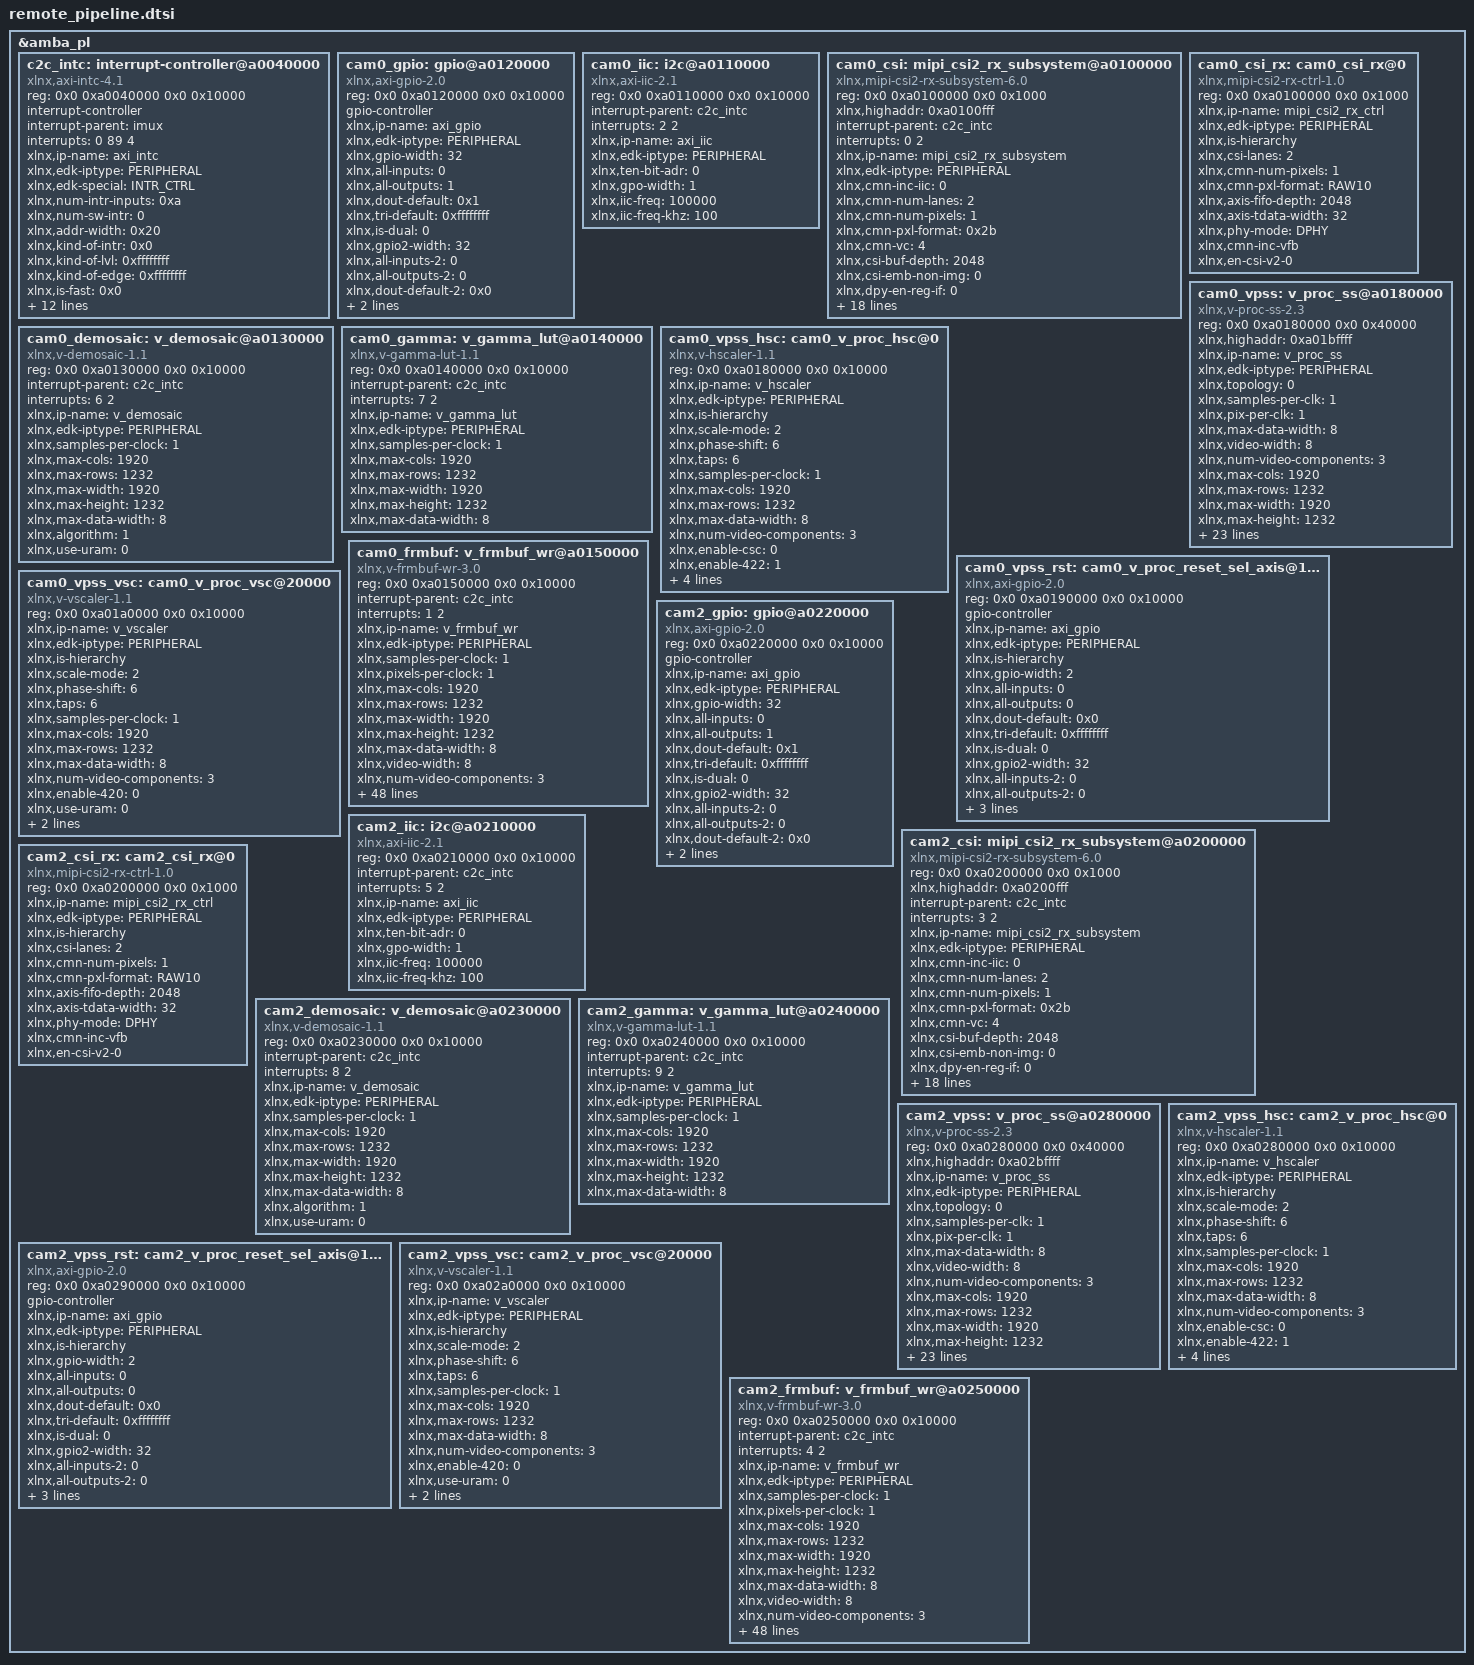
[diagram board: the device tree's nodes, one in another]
/*
 * SPDX-License-Identifier: MIT
 * Copyright (C) 2025-2026, Opsero Electronic Design Inc.  All rights reserved.
 *
 * remote_pipeline.dtsi - the "User DTS" of the Vitis System Device Tree (SDT) flow:
 * the two MIPI camera pipelines that live in the FPGA of the AUBoard 15P, described
 * for the STANDALONE (bare-metal) domain of the ZCU106.
 *
 * WHY THIS FILE EXISTS
 * --------------------
 * The ZCU106 XSA (Vivado/zcu106/c2c_wrapper.xsa) knows about the PS, the AXI
 * Chip2Chip core and one GPIO - and nothing else.  Every video IP of this design
 * sits in the OTHER FPGA and is reached through the Chip2Chip AXI4-Lite window at
 * 0xA000_0000.  Vitis cannot learn about those IP from the XSA, so we hand it this
 * device tree source: Vitis passes it to sdtgen as the "User DTS" (Create Platform
 * Component -> Advanced Options -> User DTS; on the command line the sdtgen hook
 * VITIS_SDT_INCLUDE_DTS, see Vitis/py/build-vitis.py).  Lopper then matches the
 * compatible strings to the driver YAML files of embeddedsw, pulls the drivers into
 * the BSP and generates their config tables (xv_frmbufwr_g.c, xiic_g.c, ...) with
 * the addresses below - exactly as if the IP were in the ZCU106.
 *
 * WHERE THE VALUES COME FROM
 * --------------------------
 * Every address, parameter and interrupt number below is the value the AUBoard block
 * design was built with.  Authoritative source: docs/link_contract_deviations.md
 * ("Phase 2") and Vivado/src/bd/bd_fpga.tcl, which prints them at build time on the
 * lines that start with "INFO: [cam]" and "INFO: [map]".  The Linux description of
 * the same hardware is Yocto/overlays/c2c-cams.dtso - same addresses, same interrupt
 * numbers, different (Linux) property sets.
 *
 * The property NAMES and the node shapes are the ones the AMD tools themselves
 * produce: they were harvested from an SDT generated with sdtgen from an XSA of the
 * rpi-camera-fmc reference design, which has the same IP instantiated locally, and
 * cross-checked against the "required:" list of each driver's YAML binding under
 * <Vitis>/data/embeddedsw/XilinxProcessorIPLib/drivers/ (data/<driver>.yaml).
 *
 * WHAT IS *NOT* HERE
 * ------------------
 * - clocks / clock-names: the standalone config structs do not carry a clock, and
 *   the clocks of these IP are generated on the AUBoard, where the ZCU106 tree has
 *   no phandle for them.  (The Linux overlay does need them, and invents fixed
 *   clocks for exactly that reason.)
 * - reset-gpios: a Linux-only binding.  Bare metal releases the resets by hand,
 *   through the per-pipeline axi_gpio - see Vitis/common/src/pipe.c.
 * - the axis_subset_converter (RAW10 -> 8 bit) has no register interface and no node.
 *
 * READ THIS BEFORE TOUCHING THE HARDWARE
 * --------------------------------------
 * A video IP whose reset bit in the GPIO of its pipeline is 0 does NOT answer on
 * AXI4-Lite, and neither does anything behind a link that is down.  Such an access
 * never completes and hangs the A53.  The application therefore checks the link
 * status register (0xA100_0000, in the ZCU106 XSA) first and releases every reset
 * before it touches an IP.  Nothing in this file causes an access by itself - the
 * standalone BSP only generates data structures.
 *
 * MEMORY MAP (repeated here so the file stands on its own)
 *
 *   0xA004_0000  64K   axi_intc (10 inputs, all level) -> pl_ps_irq0[0] = GIC SPI 89
 *   CAM0 0xA010_0000 / CAM2 0xA020_0000, offsets inside a pipeline:
 *     +0x0_0000  64K   mipi_csi2_rx_subsystem (decodes 4K)
 *     +0x1_0000  64K   axi_iic        (sensor bus, IMX219 at 0x10)
 *     +0x2_0000  64K   axi_gpio       (camera enable + the resets of the video IP)
 *     +0x3_0000  64K   v_demosaic
 *     +0x4_0000  64K   v_gamma_lut
 *     +0x5_0000  64K   v_frmbuf_wr
 *     +0x8_0000 256K   v_proc_ss      (+0x0_0000 h scaler, +0x1_0000 reset GPIO,
 *                                      +0x2_0000 v scaler)
 *
 *   axi_intc inputs:  0 CAM0 csi   1 CAM0 frmbuf_wr   2 CAM0 iic
 *                     3 CAM2 csi   4 CAM2 frmbuf_wr   5 CAM2 iic
 *                     6 CAM0 demosaic   7 CAM0 gamma
 *                     8 CAM2 demosaic   9 CAM2 gamma
 */

/ {
};

&amba_pl {

	/* =====================================================================
	 * The interrupt controller of the remote design.
	 *
	 * Its "irq" output crosses the link on axi_c2c_m2s_intr_in[0] and lands
	 * on the ZCU106 as pl_ps_irq0[0] = GIC SPI 89, level, active high.  The
	 * parent is &imux, the interrupt multiplexer node of zynqmp.dtsi - the
	 * same parent the AMD tools give a PL interrupt controller in a
	 * single-FPGA design (three cells: 0 = SPI, 89, 4 = level high).
	 *
	 * Consumers below use two cells, <input, sense>, sense 2 = level high.
	 *
	 * What this buys the BSP: every remote IP gets IntrId and IntrParent in
	 * its generated config struct, with IntrParent = this base address with
	 * bit 0 set (lopper's "parent is an AXI INTC, not the GIC" marker), i.e.
	 * 0xa0040001.  See docs/source/baremetal.md for why the demo application
	 * nevertheless POLLS: XSetupInterruptSystem() cannot wire an AXI INTC
	 * that hangs below the GIC on a Cortex-A53.
	 * ===================================================================== */
	c2c_intc: interrupt-controller@a0040000 {
		compatible = "xlnx,axi-intc-4.1", "xlnx,xps-intc-1.00.a";
		reg = <0x0 0xa0040000 0x0 0x10000>;
		status = "okay";
		interrupt-controller;
		#interrupt-cells = <2>;
		interrupt-parent = <&imux>;
		interrupts = <0 89 4>;
		interrupt-names = "irq";
		xlnx,ip-name = "axi_intc";
		xlnx,edk-iptype = "PERIPHERAL";
		xlnx,edk-special = "INTR_CTRL";
		xlnx,num-intr-inputs = <0xa>;
		xlnx,num-sw-intr = <0>;
		xlnx,addr-width = <0x20>;
		/* C_KIND_OF_INTR of the IP is 0xFFFFFC00; masked to the 10 inputs
		 * that exist this is 0: every input is LEVEL sensitive. */
		xlnx,kind-of-intr = <0x0>;
		xlnx,kind-of-lvl = <0xffffffff>;
		xlnx,kind-of-edge = <0xffffffff>;
		xlnx,is-fast = <0x0>;
		xlnx,has-fast = <0>;
		xlnx,ivar-rst-val = <0x10>;
		xlnx,ivar-reset-value = <0x10>;
		xlnx,has-ivr = <1>;
		xlnx,has-sie = <1>;
		xlnx,has-cie = <1>;
		xlnx,has-ipr = <1>;
		xlnx,has-ilr = <0>;
		xlnx,irq-is-level = <1>;
		xlnx,irq-active = <0x1>;
		xlnx,en-cascade-mode = <0>;
		xlnx,cascade-master = <0>;
	};

	/* =====================================================================
	 * CAM0 - 0xA010_0000
	 * ===================================================================== */

	/* Camera enable and the resets of the video IP.  32 bits, all outputs,
	 * reset value 0x1 (camera on, every video IP held in reset).
	 *   bit 0 camera enable (active high)   bit 3 v_proc_ss reset (low)
	 *   bit 2 v_demosaic reset (active low) bit 4 v_gamma_lut reset (low)
	 *   bit 6 v_frmbuf_wr reset (active low)
	 * No interrupt: C_INTERRUPT_PRESENT is 0. */
	cam0_gpio: gpio@a0120000 {
		compatible = "xlnx,axi-gpio-2.0", "xlnx,xps-gpio-1.00.a";
		reg = <0x0 0xa0120000 0x0 0x10000>;
		status = "okay";
		gpio-controller;
		#gpio-cells = <2>;
		xlnx,ip-name = "axi_gpio";
		xlnx,edk-iptype = "PERIPHERAL";
		xlnx,gpio-width = <32>;
		xlnx,all-inputs = <0>;
		xlnx,all-outputs = <1>;
		xlnx,dout-default = <0x1>;
		xlnx,tri-default = <0xffffffff>;
		xlnx,is-dual = <0>;
		xlnx,gpio2-width = <32>;
		xlnx,all-inputs-2 = <0>;
		xlnx,all-outputs-2 = <0>;
		xlnx,dout-default-2 = <0x0>;
		xlnx,tri-default-2 = <0xffffffff>;
		xlnx,interrupt-present = <0>;
	};

	/* Sensor bus: 100 kHz, 7 bit addressing, one AXI IIC per camera. */
	cam0_iic: i2c@a0110000 {
		compatible = "xlnx,axi-iic-2.1", "xlnx,xps-iic-2.00.a";
		reg = <0x0 0xa0110000 0x0 0x10000>;
		status = "okay";
		interrupt-parent = <&c2c_intc>;
		interrupts = <2 2>;
		interrupt-names = "iic2intc_irpt";
		#address-cells = <1>;
		#size-cells = <0>;
		xlnx,ip-name = "axi_iic";
		xlnx,edk-iptype = "PERIPHERAL";
		xlnx,ten-bit-adr = <0>;
		xlnx,gpo-width = <1>;
		xlnx,iic-freq = <100000>;
		xlnx,iic-freq-khz = <100>;
	};

	/* MIPI CSI-2 RX subsystem: 2 lanes, RAW10 (data type 0x2B), 1 pixel per
	 * clock, video format bridge in, all virtual channels, CSI-2 v2.0, line
	 * buffer 2048, D-PHY 420 Mb/s, no D-PHY register interface.  The IP
	 * decodes 4K of its 64K slot (the CSI-2 RX controller), hence the reg
	 * size and highaddr below.
	 *
	 * KNOWN TOOL ISSUE (Vitis 2025.2, NOT caused by this file): the driver's
	 * binding (mipicsiss_v1_14/data/mipicsiss.yaml) has 26 entries in its
	 * "required:" list, but XCsiSs_Config only has 24 slots in a design with
	 * no separate MIPI RX PHY IP - the last three fields of the struct are
	 * behind "#if (XPAR_XMIPI_RX_PHY_NUM_INSTANCES > 0)".  The generated
	 * xcsiss_g.c therefore overflows the struct ("excess elements in struct
	 * initializer" at build time) and EnableVCx / IntrId / IntrParent of
	 * XCsiSs_Config come out wrong.  Any design with a local
	 * mipi_csi2_rx_subsystem 6.0 hits this.  It does not matter here: the
	 * subsystem needs no register write to receive and the application never
	 * uses the XCsiSs driver (as in the rpi-camera-fmc reference design).
	 * Do not trust XCsiSs_Config until AMD fixes the binding. */
	cam0_csi: mipi_csi2_rx_subsystem@a0100000 {
		compatible = "xlnx,mipi-csi2-rx-subsystem-6.0",
			     "xlnx,mipi-csi2-rx-subsystem-5.0";
		reg = <0x0 0xa0100000 0x0 0x1000>;
		xlnx,highaddr = <0xa0100fff>;
		status = "okay";
		interrupt-parent = <&c2c_intc>;
		interrupts = <0 2>;
		interrupt-names = "csirxss_csi_irq";
		xlnx,ip-name = "mipi_csi2_rx_subsystem";
		xlnx,edk-iptype = "PERIPHERAL";
		xlnx,cmn-inc-iic = <0>;
		xlnx,cmn-num-lanes = <2>;
		xlnx,cmn-num-pixels = <1>;
		xlnx,cmn-pxl-format = <0x2b>;
		xlnx,cmn-vc = <4>;
		xlnx,csi-buf-depth = <2048>;
		xlnx,csi-emb-non-img = <0>;
		xlnx,dpy-en-reg-if = <0>;
		xlnx,dpy-line-rate = <420>;
		xlnx,hs-line-rate = <420>;
		xlnx,hs-settle-ns = <158>;
		xlnx,csi-en-crc = <1>;
		xlnx,csi-en-activelanes = <0>;
		xlnx,en-csi-v2 = <1>;
		xlnx,dphy-lanes = <2>;
		xlnx,max-lanes = <2>;
		xlnx,ppc = <1>;
		xlnx,vc = <4>;
		xlnx,en-vcx = <0>;
		xlnx,csi-pxl-format = <0x2b>;
		xlnx,axis-tdata-width = <32>;
		xlnx,cmn-inc-vfb;
		xlnx,vfb;
		xlnx,en-csi-v2-0;
		csirx-present = <1>;
		csirx-connected = <&cam0_csi_rx>;
	};

	/* The CSI-2 RX controller sub-core of the subsystem above.  It has no
	 * driver of its own; the subsystem driver reaches it through
	 * csirx-connected, and lopper needs the node to resolve that phandle. */
	cam0_csi_rx: cam0_csi_rx@0 {
		compatible = "xlnx,mipi-csi2-rx-ctrl-1.0";
		reg = <0x0 0xa0100000 0x0 0x1000>;
		status = "okay";
		xlnx,ip-name = "mipi_csi2_rx_ctrl";
		xlnx,edk-iptype = "PERIPHERAL";
		xlnx,is-hierarchy;
		xlnx,csi-lanes = <2>;
		xlnx,cmn-num-pixels = <1>;
		xlnx,cmn-pxl-format = "RAW10";
		xlnx,axis-fifo-depth = <2048>;
		xlnx,axis-tdata-width = <32>;
		xlnx,phy-mode = "DPHY";
		xlnx,cmn-inc-vfb;
		xlnx,en-csi-v2-0;
	};

	/* Bayer -> RGB.  8 bit, 1 sample per clock, max 1920 x 1232,
	 * ALGORITHM 1, zipper removal on.  Bayer phase is a run-time register
	 * (RGGB = 0 for the IMX219). */
	cam0_demosaic: v_demosaic@a0130000 {
		compatible = "xlnx,v-demosaic-1.1", "xlnx,v-demosaic";
		reg = <0x0 0xa0130000 0x0 0x10000>;
		status = "okay";
		interrupt-parent = <&c2c_intc>;
		interrupts = <6 2>;
		interrupt-names = "interrupt";
		xlnx,ip-name = "v_demosaic";
		xlnx,edk-iptype = "PERIPHERAL";
		xlnx,samples-per-clock = <1>;
		xlnx,max-cols = <1920>;
		xlnx,max-rows = <1232>;
		xlnx,max-width = <1920>;
		xlnx,max-height = <1232>;
		xlnx,max-data-width = <8>;
		xlnx,algorithm = <1>;
		xlnx,use-uram = <0>;
	};

	/* Gamma LUT.  8 bit, 1 sample per clock, max 1920 x 1232.  The three
	 * 256-entry tables live at +0x800 / +0x1000 / +0x1800 and power up
	 * LINEAR - the application loads a real curve. */
	cam0_gamma: v_gamma_lut@a0140000 {
		compatible = "xlnx,v-gamma-lut-1.1", "xlnx,v-gamma-lut";
		reg = <0x0 0xa0140000 0x0 0x10000>;
		status = "okay";
		interrupt-parent = <&c2c_intc>;
		interrupts = <7 2>;
		interrupt-names = "interrupt";
		xlnx,ip-name = "v_gamma_lut";
		xlnx,edk-iptype = "PERIPHERAL";
		xlnx,samples-per-clock = <1>;
		xlnx,max-cols = <1920>;
		xlnx,max-rows = <1232>;
		xlnx,max-width = <1920>;
		xlnx,max-height = <1232>;
		xlnx,max-data-width = <8>;
	};

	/* Video Processing Subsystem, scaler only (C_TOPOLOGY 0), polyphase,
	 * 6 taps / 64 phases horizontal and vertical, 8 bit, 1 sample per clock,
	 * max 1920 x 1232, no colour space conversion, RGB / YUV 4:4:4 only,
	 * no DMA.  The 256K window holds the three sub-cores below. */
	cam0_vpss: v_proc_ss@a0180000 {
		compatible = "xlnx,v-proc-ss-2.3", "xlnx,v-vpss-scaler-2.2";
		reg = <0x0 0xa0180000 0x0 0x40000>;
		xlnx,highaddr = <0xa01bffff>;
		status = "okay";
		xlnx,ip-name = "v_proc_ss";
		xlnx,edk-iptype = "PERIPHERAL";
		xlnx,topology = <0>;
		xlnx,samples-per-clk = <1>;
		xlnx,pix-per-clk = <1>;
		xlnx,max-data-width = <8>;
		xlnx,video-width = <8>;
		xlnx,num-video-components = <3>;
		xlnx,max-cols = <1920>;
		xlnx,max-rows = <1232>;
		xlnx,max-width = <1920>;
		xlnx,max-height = <1232>;
		xlnx,num-hori-taps = <6>;
		xlnx,num-vert-taps = <6>;
		xlnx,h-scaler-taps = <6>;
		xlnx,v-scaler-taps = <6>;
		xlnx,h-scaler-phases = <64>;
		xlnx,v-scaler-phases = <64>;
		xlnx,max-num-phases = <64>;
		xlnx,scaler-algorithm = <2>;
		xlnx,colorspace-support = <2>;
		xlnx,deint-motion-adaptive;
		xlnx,enable-interlaced;
		rstaxis-present = <1>;
		rstaxis-connected = <&cam0_vpss_rst>;
		hscale-present = <1>;
		hscale-connected = <&cam0_vpss_hsc>;
		vscale-present = <1>;
		vscale-connected = <&cam0_vpss_vsc>;
		csc-present = <0>;
		deint-present = <0>;
		hcrsmplr-present = <0>;
		lbox-present = <0>;
		router-present = <0>;
		vdma-present = <0>;
	};

	cam0_vpss_hsc: cam0_v_proc_hsc@0 {
		compatible = "xlnx,v-hscaler-1.1";
		reg = <0x0 0xa0180000 0x0 0x10000>;
		status = "okay";
		xlnx,ip-name = "v_hscaler";
		xlnx,edk-iptype = "PERIPHERAL";
		xlnx,is-hierarchy;
		xlnx,scale-mode = <2>;
		xlnx,phase-shift = <6>;
		xlnx,taps = <6>;
		xlnx,samples-per-clock = <1>;
		xlnx,max-cols = <1920>;
		xlnx,max-rows = <1232>;
		xlnx,max-data-width = <8>;
		xlnx,num-video-components = <3>;
		xlnx,enable-csc = <0>;
		xlnx,enable-422 = <1>;
		xlnx,enable-420 = <0>;
		xlnx,use-uram = <0>;
		xlnx,s-axi-ctrl-addr-width = <16>;
		xlnx,s-axi-ctrl-data-width = <32>;
	};

	/* The reset GPIO inside v_proc_ss: 2 bits, bit 1 resets both scalers
	 * (active low, reset value 0).  The subsystem driver drives it. */
	cam0_vpss_rst: cam0_v_proc_reset_sel_axis@10000 {
		compatible = "xlnx,axi-gpio-2.0", "xlnx,xps-gpio-1.00.a";
		reg = <0x0 0xa0190000 0x0 0x10000>;
		status = "okay";
		gpio-controller;
		#gpio-cells = <2>;
		xlnx,ip-name = "axi_gpio";
		xlnx,edk-iptype = "PERIPHERAL";
		xlnx,is-hierarchy;
		xlnx,gpio-width = <2>;
		xlnx,all-inputs = <0>;
		xlnx,all-outputs = <0>;
		xlnx,dout-default = <0x0>;
		xlnx,tri-default = <0xffffffff>;
		xlnx,is-dual = <0>;
		xlnx,gpio2-width = <32>;
		xlnx,all-inputs-2 = <0>;
		xlnx,all-outputs-2 = <0>;
		xlnx,dout-default-2 = <0x0>;
		xlnx,tri-default-2 = <0xffffffff>;
		xlnx,interrupt-present = <0>;
	};

	cam0_vpss_vsc: cam0_v_proc_vsc@20000 {
		compatible = "xlnx,v-vscaler-1.1";
		reg = <0x0 0xa01a0000 0x0 0x10000>;
		status = "okay";
		xlnx,ip-name = "v_vscaler";
		xlnx,edk-iptype = "PERIPHERAL";
		xlnx,is-hierarchy;
		xlnx,scale-mode = <2>;
		xlnx,phase-shift = <6>;
		xlnx,taps = <6>;
		xlnx,samples-per-clock = <1>;
		xlnx,max-cols = <1920>;
		xlnx,max-rows = <1232>;
		xlnx,max-data-width = <8>;
		xlnx,num-video-components = <3>;
		xlnx,enable-420 = <0>;
		xlnx,use-uram = <0>;
		xlnx,s-axi-ctrl-addr-width = <12>;
		xlnx,s-axi-ctrl-data-width = <32>;
	};

	/* Frame buffer write - the end of the pipeline.  RGB8 is the ONLY
	 * memory format enabled in the IP (3 bytes per pixel).  Its AXI4 master
	 * is 64 bit wide with 32 bit addresses and reaches only 0x0000_0000 -
	 * 0x7FFF_FFFF of the ZCU106 (DDR low, through S_AXI_HP0_FPD); anything
	 * above that gets a DECERR.  Stride must be a multiple of 8 bytes. */
	cam0_frmbuf: v_frmbuf_wr@a0150000 {
		compatible = "xlnx,v-frmbuf-wr-3.0", "xlnx,axi-frmbuf-wr-v2.2";
		reg = <0x0 0xa0150000 0x0 0x10000>;
		status = "okay";
		interrupt-parent = <&c2c_intc>;
		interrupts = <1 2>;
		interrupt-names = "interrupt";
		#dma-cells = <1>;
		xlnx,ip-name = "v_frmbuf_wr";
		xlnx,edk-iptype = "PERIPHERAL";
		xlnx,samples-per-clock = <1>;
		xlnx,pixels-per-clock = <1>;
		xlnx,max-cols = <1920>;
		xlnx,max-rows = <1232>;
		xlnx,max-width = <1920>;
		xlnx,max-height = <1232>;
		xlnx,max-data-width = <8>;
		xlnx,video-width = <8>;
		xlnx,num-video-components = <3>;
		xlnx,aximm-data-width = <64>;
		xlnx,aximm-addr-width = <32>;
		xlnx,aximm-burst-length = <64>;
		xlnx,aximm-num-outstanding = <4>;
		xlnx,dma-addr-width = <32>;
		xlnx,dma-align = <8>;
		xlnx,vid-formats = "bgr888";
		xlnx,has-rgb8 = <1>;
		xlnx,has-bgr8 = <0>;
		xlnx,has-rgbx8 = <0>;
		xlnx,has-bgrx8 = <0>;
		xlnx,has-rgba8 = <0>;
		xlnx,has-bgra8 = <0>;
		xlnx,has-yuv8 = <0>;
		xlnx,has-yuvx8 = <0>;
		xlnx,has-yuva8 = <0>;
		xlnx,has-yuyv8 = <0>;
		xlnx,has-uyvy8 = <0>;
		xlnx,has-y-uv8 = <0>;
		xlnx,has-y-uv8-420 = <0>;
		xlnx,has-y8 = <0>;
		xlnx,has-rgbx10 = <0>;
		xlnx,has-yuvx10 = <0>;
		xlnx,has-y-uv10 = <0>;
		xlnx,has-y-uv10-420 = <0>;
		xlnx,has-y10 = <0>;
		xlnx,has-rgbx12 = <0>;
		xlnx,has-yuvx12 = <0>;
		xlnx,has-y-uv12 = <0>;
		xlnx,has-y-uv12-420 = <0>;
		xlnx,has-y12 = <0>;
		xlnx,has-rgb16 = <0>;
		xlnx,has-yuv16 = <0>;
		xlnx,has-y-uv16 = <0>;
		xlnx,has-y-uv16-420 = <0>;
		xlnx,has-y16 = <0>;
		xlnx,has-y-u-v8 = <0>;
		xlnx,has-y-u-v8-420 = <0>;
		xlnx,has-y-u-v10 = <0>;
		xlnx,has-y-u-v12 = <0>;
		xlnx,has-interlaced = <0>;
		xlnx,is-tile-format = <0>;
		xlnx,enable-sync-signals = <0>;
		xlnx,has-alpha = <0>;
		xlnx,use-uram = <0>;
		xlnx,max-nr-planes = <2>;
		xlnx,s-axi-ctrl-addr-width = <0x7>;
		xlnx,s-axi-ctrl-data-width = <0x20>;
	};

	/* =====================================================================
	 * CAM2 - 0xA020_0000.  Identical to CAM0, see the comments there; only
	 * the addresses and the axi_intc input numbers differ.
	 * ===================================================================== */

	cam2_gpio: gpio@a0220000 {
		compatible = "xlnx,axi-gpio-2.0", "xlnx,xps-gpio-1.00.a";
		reg = <0x0 0xa0220000 0x0 0x10000>;
		status = "okay";
		gpio-controller;
		#gpio-cells = <2>;
		xlnx,ip-name = "axi_gpio";
		xlnx,edk-iptype = "PERIPHERAL";
		xlnx,gpio-width = <32>;
		xlnx,all-inputs = <0>;
		xlnx,all-outputs = <1>;
		xlnx,dout-default = <0x1>;
		xlnx,tri-default = <0xffffffff>;
		xlnx,is-dual = <0>;
		xlnx,gpio2-width = <32>;
		xlnx,all-inputs-2 = <0>;
		xlnx,all-outputs-2 = <0>;
		xlnx,dout-default-2 = <0x0>;
		xlnx,tri-default-2 = <0xffffffff>;
		xlnx,interrupt-present = <0>;
	};

	cam2_iic: i2c@a0210000 {
		compatible = "xlnx,axi-iic-2.1", "xlnx,xps-iic-2.00.a";
		reg = <0x0 0xa0210000 0x0 0x10000>;
		status = "okay";
		interrupt-parent = <&c2c_intc>;
		interrupts = <5 2>;
		interrupt-names = "iic2intc_irpt";
		#address-cells = <1>;
		#size-cells = <0>;
		xlnx,ip-name = "axi_iic";
		xlnx,edk-iptype = "PERIPHERAL";
		xlnx,ten-bit-adr = <0>;
		xlnx,gpo-width = <1>;
		xlnx,iic-freq = <100000>;
		xlnx,iic-freq-khz = <100>;
	};

	cam2_csi: mipi_csi2_rx_subsystem@a0200000 {
		compatible = "xlnx,mipi-csi2-rx-subsystem-6.0",
			     "xlnx,mipi-csi2-rx-subsystem-5.0";
		reg = <0x0 0xa0200000 0x0 0x1000>;
		xlnx,highaddr = <0xa0200fff>;
		status = "okay";
		interrupt-parent = <&c2c_intc>;
		interrupts = <3 2>;
		interrupt-names = "csirxss_csi_irq";
		xlnx,ip-name = "mipi_csi2_rx_subsystem";
		xlnx,edk-iptype = "PERIPHERAL";
		xlnx,cmn-inc-iic = <0>;
		xlnx,cmn-num-lanes = <2>;
		xlnx,cmn-num-pixels = <1>;
		xlnx,cmn-pxl-format = <0x2b>;
		xlnx,cmn-vc = <4>;
		xlnx,csi-buf-depth = <2048>;
		xlnx,csi-emb-non-img = <0>;
		xlnx,dpy-en-reg-if = <0>;
		xlnx,dpy-line-rate = <420>;
		xlnx,hs-line-rate = <420>;
		xlnx,hs-settle-ns = <158>;
		xlnx,csi-en-crc = <1>;
		xlnx,csi-en-activelanes = <0>;
		xlnx,en-csi-v2 = <1>;
		xlnx,dphy-lanes = <2>;
		xlnx,max-lanes = <2>;
		xlnx,ppc = <1>;
		xlnx,vc = <4>;
		xlnx,en-vcx = <0>;
		xlnx,csi-pxl-format = <0x2b>;
		xlnx,axis-tdata-width = <32>;
		xlnx,cmn-inc-vfb;
		xlnx,vfb;
		xlnx,en-csi-v2-0;
		csirx-present = <1>;
		csirx-connected = <&cam2_csi_rx>;
	};

	cam2_csi_rx: cam2_csi_rx@0 {
		compatible = "xlnx,mipi-csi2-rx-ctrl-1.0";
		reg = <0x0 0xa0200000 0x0 0x1000>;
		status = "okay";
		xlnx,ip-name = "mipi_csi2_rx_ctrl";
		xlnx,edk-iptype = "PERIPHERAL";
		xlnx,is-hierarchy;
		xlnx,csi-lanes = <2>;
		xlnx,cmn-num-pixels = <1>;
		xlnx,cmn-pxl-format = "RAW10";
		xlnx,axis-fifo-depth = <2048>;
		xlnx,axis-tdata-width = <32>;
		xlnx,phy-mode = "DPHY";
		xlnx,cmn-inc-vfb;
		xlnx,en-csi-v2-0;
	};

	cam2_demosaic: v_demosaic@a0230000 {
		compatible = "xlnx,v-demosaic-1.1", "xlnx,v-demosaic";
		reg = <0x0 0xa0230000 0x0 0x10000>;
		status = "okay";
		interrupt-parent = <&c2c_intc>;
		interrupts = <8 2>;
		interrupt-names = "interrupt";
		xlnx,ip-name = "v_demosaic";
		xlnx,edk-iptype = "PERIPHERAL";
		xlnx,samples-per-clock = <1>;
		xlnx,max-cols = <1920>;
		xlnx,max-rows = <1232>;
		xlnx,max-width = <1920>;
		xlnx,max-height = <1232>;
		xlnx,max-data-width = <8>;
		xlnx,algorithm = <1>;
		xlnx,use-uram = <0>;
	};

	cam2_gamma: v_gamma_lut@a0240000 {
		compatible = "xlnx,v-gamma-lut-1.1", "xlnx,v-gamma-lut";
		reg = <0x0 0xa0240000 0x0 0x10000>;
		status = "okay";
		interrupt-parent = <&c2c_intc>;
		interrupts = <9 2>;
		interrupt-names = "interrupt";
		xlnx,ip-name = "v_gamma_lut";
		xlnx,edk-iptype = "PERIPHERAL";
		xlnx,samples-per-clock = <1>;
		xlnx,max-cols = <1920>;
		xlnx,max-rows = <1232>;
		xlnx,max-width = <1920>;
		xlnx,max-height = <1232>;
		xlnx,max-data-width = <8>;
	};

	cam2_vpss: v_proc_ss@a0280000 {
		compatible = "xlnx,v-proc-ss-2.3", "xlnx,v-vpss-scaler-2.2";
		reg = <0x0 0xa0280000 0x0 0x40000>;
		xlnx,highaddr = <0xa02bffff>;
		status = "okay";
		xlnx,ip-name = "v_proc_ss";
		xlnx,edk-iptype = "PERIPHERAL";
		xlnx,topology = <0>;
		xlnx,samples-per-clk = <1>;
		xlnx,pix-per-clk = <1>;
		xlnx,max-data-width = <8>;
		xlnx,video-width = <8>;
		xlnx,num-video-components = <3>;
		xlnx,max-cols = <1920>;
		xlnx,max-rows = <1232>;
		xlnx,max-width = <1920>;
		xlnx,max-height = <1232>;
		xlnx,num-hori-taps = <6>;
		xlnx,num-vert-taps = <6>;
		xlnx,h-scaler-taps = <6>;
		xlnx,v-scaler-taps = <6>;
		xlnx,h-scaler-phases = <64>;
		xlnx,v-scaler-phases = <64>;
		xlnx,max-num-phases = <64>;
		xlnx,scaler-algorithm = <2>;
		xlnx,colorspace-support = <2>;
		xlnx,deint-motion-adaptive;
		xlnx,enable-interlaced;
		rstaxis-present = <1>;
		rstaxis-connected = <&cam2_vpss_rst>;
		hscale-present = <1>;
		hscale-connected = <&cam2_vpss_hsc>;
		vscale-present = <1>;
		vscale-connected = <&cam2_vpss_vsc>;
		csc-present = <0>;
		deint-present = <0>;
		hcrsmplr-present = <0>;
		lbox-present = <0>;
		router-present = <0>;
		vdma-present = <0>;
	};

	cam2_vpss_hsc: cam2_v_proc_hsc@0 {
		compatible = "xlnx,v-hscaler-1.1";
		reg = <0x0 0xa0280000 0x0 0x10000>;
		status = "okay";
		xlnx,ip-name = "v_hscaler";
		xlnx,edk-iptype = "PERIPHERAL";
		xlnx,is-hierarchy;
		xlnx,scale-mode = <2>;
		xlnx,phase-shift = <6>;
		xlnx,taps = <6>;
		xlnx,samples-per-clock = <1>;
		xlnx,max-cols = <1920>;
		xlnx,max-rows = <1232>;
		xlnx,max-data-width = <8>;
		xlnx,num-video-components = <3>;
		xlnx,enable-csc = <0>;
		xlnx,enable-422 = <1>;
		xlnx,enable-420 = <0>;
		xlnx,use-uram = <0>;
		xlnx,s-axi-ctrl-addr-width = <16>;
		xlnx,s-axi-ctrl-data-width = <32>;
	};

	cam2_vpss_rst: cam2_v_proc_reset_sel_axis@10000 {
		compatible = "xlnx,axi-gpio-2.0", "xlnx,xps-gpio-1.00.a";
		reg = <0x0 0xa0290000 0x0 0x10000>;
		status = "okay";
		gpio-controller;
		#gpio-cells = <2>;
		xlnx,ip-name = "axi_gpio";
		xlnx,edk-iptype = "PERIPHERAL";
		xlnx,is-hierarchy;
		xlnx,gpio-width = <2>;
		xlnx,all-inputs = <0>;
		xlnx,all-outputs = <0>;
		xlnx,dout-default = <0x0>;
		xlnx,tri-default = <0xffffffff>;
		xlnx,is-dual = <0>;
		xlnx,gpio2-width = <32>;
		xlnx,all-inputs-2 = <0>;
		xlnx,all-outputs-2 = <0>;
		xlnx,dout-default-2 = <0x0>;
		xlnx,tri-default-2 = <0xffffffff>;
		xlnx,interrupt-present = <0>;
	};

	cam2_vpss_vsc: cam2_v_proc_vsc@20000 {
		compatible = "xlnx,v-vscaler-1.1";
		reg = <0x0 0xa02a0000 0x0 0x10000>;
		status = "okay";
		xlnx,ip-name = "v_vscaler";
		xlnx,edk-iptype = "PERIPHERAL";
		xlnx,is-hierarchy;
		xlnx,scale-mode = <2>;
		xlnx,phase-shift = <6>;
		xlnx,taps = <6>;
		xlnx,samples-per-clock = <1>;
		xlnx,max-cols = <1920>;
		xlnx,max-rows = <1232>;
		xlnx,max-data-width = <8>;
		xlnx,num-video-components = <3>;
		xlnx,enable-420 = <0>;
		xlnx,use-uram = <0>;
		xlnx,s-axi-ctrl-addr-width = <12>;
		xlnx,s-axi-ctrl-data-width = <32>;
	};

	cam2_frmbuf: v_frmbuf_wr@a0250000 {
		compatible = "xlnx,v-frmbuf-wr-3.0", "xlnx,axi-frmbuf-wr-v2.2";
		reg = <0x0 0xa0250000 0x0 0x10000>;
		status = "okay";
		interrupt-parent = <&c2c_intc>;
		interrupts = <4 2>;
		interrupt-names = "interrupt";
		#dma-cells = <1>;
		xlnx,ip-name = "v_frmbuf_wr";
		xlnx,edk-iptype = "PERIPHERAL";
		xlnx,samples-per-clock = <1>;
		xlnx,pixels-per-clock = <1>;
		xlnx,max-cols = <1920>;
		xlnx,max-rows = <1232>;
		xlnx,max-width = <1920>;
		xlnx,max-height = <1232>;
		xlnx,max-data-width = <8>;
		xlnx,video-width = <8>;
		xlnx,num-video-components = <3>;
		xlnx,aximm-data-width = <64>;
		xlnx,aximm-addr-width = <32>;
		xlnx,aximm-burst-length = <64>;
		xlnx,aximm-num-outstanding = <4>;
		xlnx,dma-addr-width = <32>;
		xlnx,dma-align = <8>;
		xlnx,vid-formats = "bgr888";
		xlnx,has-rgb8 = <1>;
		xlnx,has-bgr8 = <0>;
		xlnx,has-rgbx8 = <0>;
		xlnx,has-bgrx8 = <0>;
		xlnx,has-rgba8 = <0>;
		xlnx,has-bgra8 = <0>;
		xlnx,has-yuv8 = <0>;
		xlnx,has-yuvx8 = <0>;
		xlnx,has-yuva8 = <0>;
		xlnx,has-yuyv8 = <0>;
		xlnx,has-uyvy8 = <0>;
		xlnx,has-y-uv8 = <0>;
		xlnx,has-y-uv8-420 = <0>;
		xlnx,has-y8 = <0>;
		xlnx,has-rgbx10 = <0>;
		xlnx,has-yuvx10 = <0>;
		xlnx,has-y-uv10 = <0>;
		xlnx,has-y-uv10-420 = <0>;
		xlnx,has-y10 = <0>;
		xlnx,has-rgbx12 = <0>;
		xlnx,has-yuvx12 = <0>;
		xlnx,has-y-uv12 = <0>;
		xlnx,has-y-uv12-420 = <0>;
		xlnx,has-y12 = <0>;
		xlnx,has-rgb16 = <0>;
		xlnx,has-yuv16 = <0>;
		xlnx,has-y-uv16 = <0>;
		xlnx,has-y-uv16-420 = <0>;
		xlnx,has-y16 = <0>;
		xlnx,has-y-u-v8 = <0>;
		xlnx,has-y-u-v8-420 = <0>;
		xlnx,has-y-u-v10 = <0>;
		xlnx,has-y-u-v12 = <0>;
		xlnx,has-interlaced = <0>;
		xlnx,is-tile-format = <0>;
		xlnx,enable-sync-signals = <0>;
		xlnx,has-alpha = <0>;
		xlnx,use-uram = <0>;
		xlnx,max-nr-planes = <2>;
		xlnx,s-axi-ctrl-addr-width = <0x7>;
		xlnx,s-axi-ctrl-data-width = <0x20>;
	};
};
